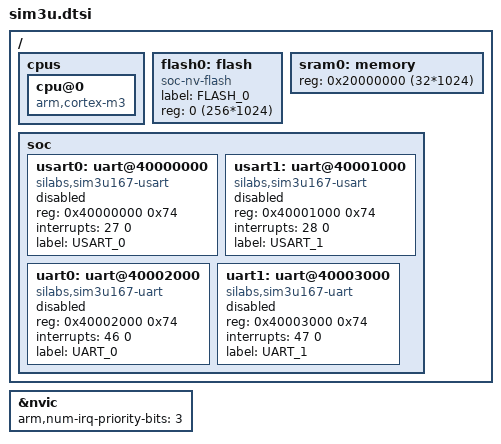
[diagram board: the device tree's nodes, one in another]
#include <arm/armv7-m.dtsi>

/ {
	cpus {
		cpu@0 {
			compatible = "arm,cortex-m3";
		};
	};

	flash0: flash {
		compatible = "soc-nv-flash";
		label = "FLASH_0";
		reg = <0 (256*1024)>;
	};

	sram0: memory {
		reg = <0x20000000 (32*1024)>;
	};

	soc {
		usart0: uart@40000000 { /* USART0 */
			compatible = "silabs,sim3u167-usart";
			reg = <0x40000000 0x74>;
			interrupts = <27 0>;
			status = "disabled";
			label = "USART_0";
		};

		usart1: uart@40001000 { /* USART1 */
			compatible = "silabs,sim3u167-usart";
			reg = <0x40001000 0x74>;
			interrupts = <28 0>;
			status = "disabled";
			label = "USART_1";
		};

		uart0: uart@40002000 { /* UART0 */
			compatible = "silabs,sim3u167-uart";
			reg = <0x40002000 0x74>;
			interrupts = <46 0>;
			status = "disabled";
			label = "UART_0";
		};

		uart1: uart@40003000 { /* UART1 */
			compatible = "silabs,sim3u167-uart";
			reg = <0x40003000 0x74>;
			interrupts = <47 0>;
			status = "disabled";
			label = "UART_1";
		};
	};
};

&nvic {
	arm,num-irq-priority-bits = <3>;
};
